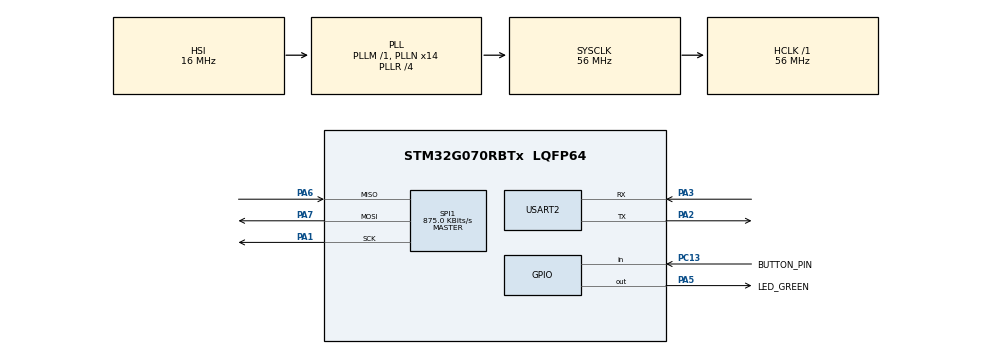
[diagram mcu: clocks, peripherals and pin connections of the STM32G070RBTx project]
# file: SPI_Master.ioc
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Mcu.Family=STM32G0
Mcu.Name=STM32G070RBTx
Mcu.Package=LQFP64
NVIC.SPI1_IRQn=true\:0\:0\:false\:false\:true\:true\:true\:true
PA1.GPIO_Speed=GPIO_SPEED_FREQ_VERY_HIGH
PA1.Mode=Full_Duplex_Master
PA1.Signal=SPI1_SCK
PA13.GPIO_Label=TMS
PA13.Mode=Serial_Wire
PA13.Signal=SYS_SWDIO
PA14-BOOT0.GPIO_Label=TCK
PA14-BOOT0.Mode=Serial_Wire
PA14-BOOT0.Signal=SYS_SWCLK
PA2.GPIO_PuPd=GPIO_PULLUP
PA2.Mode=Asynchronous
PA2.Signal=USART2_TX
PA3.GPIO_PuPd=GPIO_PULLUP
PA3.Mode=Asynchronous
PA3.Signal=USART2_RX
PA5.GPIO_Label=LED_GREEN
PA5.GPIO_Speed=GPIO_SPEED_FREQ_HIGH
PA5.Signal=GPIO_Output
PA6.GPIO_Speed=GPIO_SPEED_FREQ_VERY_HIGH
PA6.Mode=Full_Duplex_Master
PA6.Signal=SPI1_MISO
PA7.GPIO_Speed=GPIO_SPEED_FREQ_VERY_HIGH
PA7.Mode=Full_Duplex_Master
PA7.Signal=SPI1_MOSI
PC13.GPIO_Label=BUTTON_PIN
PC13.Signal=GPIO_Input
PC14-OSC32_IN\ (PC14).Mode=LSE-External-Oscillator
PC14-OSC32_IN\ (PC14).Signal=RCC_OSC32_IN
PC15-OSC32_OUT\ (PC15).Mode=LSE-External-Oscillator
PC15-OSC32_OUT\ (PC15).Signal=RCC_OSC32_OUT
PF0-OSC_IN\ (PF0).GPIO_Label=MCO
PF0-OSC_IN\ (PF0).Mode=HSE-External-Clock-Source
PF0-OSC_IN\ (PF0).Signal=RCC_OSC_IN
ProjectManager.HeapSize=0x200
ProjectManager.StackSize=0x400
ProjectManager.TargetToolchain=STM32CubeIDE
RCC.ADCFreq_Value=56000000
RCC.AHBFreq_Value=56000000
RCC.CortexFreq_Value=56000000
RCC.EXTERNAL_CLOCK_VALUE=12288000
RCC.HCLKFreq_Value=56000000
RCC.HSE_VALUE=8000000
RCC.HSI_VALUE=16000000
RCC.PLLN=14
RCC.PLLR=RCC_PLLR_DIV4
RCC.SYSCLKFreq_VALUE=56000000
RCC.SYSCLKSource=RCC_SYSCLKSOURCE_PLLCLK
RCC.VCOOutputFreq_Value=224000000
SPI1.BaudRatePrescaler=SPI_BAUDRATEPRESCALER_64
SPI1.CalculateBaudRate=875.0 KBits/s
SPI1.Direction=SPI_DIRECTION_2LINES
SPI1.Mode=SPI_MODE_MASTER
SPI1.VirtualType=VM_MASTER
USART2.VirtualMode-Asynchronous=VM_ASYNC
USART2.WordLength=WORDLENGTH_7B
board=NUCLEO-G070RB

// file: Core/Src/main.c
/* USER CODE BEGIN Header */
/**
  ******************************************************************************
  * @file           : main.c
  * @brief          : Main program body
  ******************************************************************************
  * @attention
  *
  * Copyright (c) 2024 STMicroelectronics.
  * All rights reserved.
  *
  * This software is licensed under terms that can be found in the LICENSE file
  * in the root directory of this software component.
  * If no LICENSE file comes with this software, it is provided AS-IS.
  *
  ******************************************************************************
  */
/* USER CODE END Header */
#include "main.h"

SPI_HandleTypeDef hspi1;

UART_HandleTypeDef huart2;

/* USER CODE BEGIN PV */
/* Private variables */
uint8_t TX_Buffer = 6 ; // DATA to send
/* USER CODE END PV */

void SystemClock_Config(void);
static void MX_GPIO_Init(void);
static void MX_USART2_UART_Init(void);
static void MX_SPI1_Init(void);

int main(void)
{

  /* MCU Configuration--------------------------------------------------------*/

  /* Reset of all peripherals, Initializes the Flash interface and the Systick. */
  HAL_Init();

  /* Configure the system clock */
  SystemClock_Config();

  /* Initialize all configured peripherals */
  MX_GPIO_Init();
  MX_USART2_UART_Init();
  MX_SPI1_Init();
  /* USER CODE BEGIN 2 */
  /* Configure LED4 */
  while (HAL_GPIO_ReadPin(BUTTON_PIN_GPIO_Port, BUTTON_PIN_Pin))
    {
	  HAL_GPIO_TogglePin(LED_GREEN_GPIO_Port, LED_GREEN_Pin);
      HAL_Delay(100);
    }
  HAL_GPIO_WritePin(LED_GREEN_GPIO_Port, LED_GREEN_Pin, 0);

//
  HAL_SPI_Transmit(&hspi1, &TX_Buffer, 1,1000); //Sending in Blocking mode
  HAL_Delay(100);
  /* USER CODE END 2 */

  /* Infinite loop */
  /* USER CODE BEGIN WHILE */
  while (1)
  {
//	  HAL_SPI_Transmit(&hspi1, &TX_Buffer, 1,1000); //Sending in Blocking mode
//	  HAL_Delay(100);
//

    /* USER CODE END WHILE */

  }
}

void SystemClock_Config(void)
{
  RCC_OscInitTypeDef RCC_OscInitStruct = {0};
  RCC_ClkInitTypeDef RCC_ClkInitStruct = {0};

  /** Configure the main internal regulator output voltage
  */
  HAL_PWREx_ControlVoltageScaling(PWR_REGULATOR_VOLTAGE_SCALE1);

  /** Initializes the RCC Oscillators according to the specified parameters
  * in the RCC_OscInitTypeDef structure.
  */
  RCC_OscInitStruct.OscillatorType = RCC_OSCILLATORTYPE_HSI;
  RCC_OscInitStruct.HSIState = RCC_HSI_ON;
  RCC_OscInitStruct.HSIDiv = RCC_HSI_DIV1;
  RCC_OscInitStruct.HSICalibrationValue = RCC_HSICALIBRATION_DEFAULT;
  RCC_OscInitStruct.PLL.PLLState = RCC_PLL_ON;
  RCC_OscInitStruct.PLL.PLLSource = RCC_PLLSOURCE_HSI;
  RCC_OscInitStruct.PLL.PLLM = RCC_PLLM_DIV1;
  RCC_OscInitStruct.PLL.PLLN = 14;
  RCC_OscInitStruct.PLL.PLLP = RCC_PLLP_DIV2;
  RCC_OscInitStruct.PLL.PLLR = RCC_PLLR_DIV4;
  if (HAL_RCC_OscConfig(&RCC_OscInitStruct) != HAL_OK)
  {
    Error_Handler();
  }

  /** Initializes the CPU, AHB and APB buses clocks
  */
  RCC_ClkInitStruct.ClockType = RCC_CLOCKTYPE_HCLK|RCC_CLOCKTYPE_SYSCLK
                              |RCC_CLOCKTYPE_PCLK1;
  RCC_ClkInitStruct.SYSCLKSource = RCC_SYSCLKSOURCE_PLLCLK;
  RCC_ClkInitStruct.AHBCLKDivider = RCC_SYSCLK_DIV1;
  RCC_ClkInitStruct.APB1CLKDivider = RCC_HCLK_DIV1;

  if (HAL_RCC_ClockConfig(&RCC_ClkInitStruct, FLASH_LATENCY_2) != HAL_OK)
  {
    Error_Handler();
  }
}

static void MX_SPI1_Init(void)
{

  /* SPI1 parameter configuration*/
  hspi1.Instance = SPI1;
  hspi1.Init.Mode = SPI_MODE_MASTER;
  hspi1.Init.Direction = SPI_DIRECTION_2LINES;
  hspi1.Init.DataSize = SPI_DATASIZE_4BIT;
  hspi1.Init.CLKPolarity = SPI_POLARITY_LOW;
  hspi1.Init.CLKPhase = SPI_PHASE_1EDGE;
  hspi1.Init.NSS = SPI_NSS_SOFT;
  hspi1.Init.BaudRatePrescaler = SPI_BAUDRATEPRESCALER_64;
  hspi1.Init.FirstBit = SPI_FIRSTBIT_MSB;
  hspi1.Init.TIMode = SPI_TIMODE_DISABLE;
  hspi1.Init.CRCCalculation = SPI_CRCCALCULATION_DISABLE;
  hspi1.Init.CRCPolynomial = 7;
  hspi1.Init.CRCLength = SPI_CRC_LENGTH_DATASIZE;
  hspi1.Init.NSSPMode = SPI_NSS_PULSE_ENABLE;
  if (HAL_SPI_Init(&hspi1) != HAL_OK)
  {
    Error_Handler();
  }

}

static void MX_USART2_UART_Init(void)
{

  huart2.Instance = USART2;
  huart2.Init.BaudRate = 115200;
  huart2.Init.WordLength = UART_WORDLENGTH_7B;
  huart2.Init.StopBits = UART_STOPBITS_1;
  huart2.Init.Parity = UART_PARITY_NONE;
  huart2.Init.Mode = UART_MODE_TX_RX;
  huart2.Init.HwFlowCtl = UART_HWCONTROL_NONE;
  huart2.Init.OverSampling = UART_OVERSAMPLING_16;
  huart2.Init.OneBitSampling = UART_ONE_BIT_SAMPLE_DISABLE;
  huart2.Init.ClockPrescaler = UART_PRESCALER_DIV1;
  huart2.AdvancedInit.AdvFeatureInit = UART_ADVFEATURE_NO_INIT;
  if (HAL_UART_Init(&huart2) != HAL_OK)
  {
    Error_Handler();
  }
  if (HAL_UARTEx_SetTxFifoThreshold(&huart2, UART_TXFIFO_THRESHOLD_1_8) != HAL_OK)
  {
    Error_Handler();
  }
  if (HAL_UARTEx_SetRxFifoThreshold(&huart2, UART_RXFIFO_THRESHOLD_1_8) != HAL_OK)
  {
    Error_Handler();
  }
  if (HAL_UARTEx_DisableFifoMode(&huart2) != HAL_OK)
  {
    Error_Handler();
  }

}

static void MX_GPIO_Init(void)
{
  GPIO_InitTypeDef GPIO_InitStruct = {0};

  /* GPIO Ports Clock Enable */
  __HAL_RCC_GPIOC_CLK_ENABLE();
  __HAL_RCC_GPIOF_CLK_ENABLE();
  __HAL_RCC_GPIOA_CLK_ENABLE();

  /*Configure GPIO pin Output Level */
  HAL_GPIO_WritePin(LED_GREEN_GPIO_Port, LED_GREEN_Pin, GPIO_PIN_RESET);

  /*Configure GPIO pin : BUTTON_PIN_Pin */
  GPIO_InitStruct.Pin = BUTTON_PIN_Pin;
  GPIO_InitStruct.Mode = GPIO_MODE_INPUT;
  GPIO_InitStruct.Pull = GPIO_NOPULL;
  HAL_GPIO_Init(BUTTON_PIN_GPIO_Port, &GPIO_InitStruct);

  /*Configure GPIO pin : LED_GREEN_Pin */
  GPIO_InitStruct.Pin = LED_GREEN_Pin;
  GPIO_InitStruct.Mode = GPIO_MODE_OUTPUT_PP;
  GPIO_InitStruct.Pull = GPIO_NOPULL;
  GPIO_InitStruct.Speed = GPIO_SPEED_FREQ_HIGH;
  HAL_GPIO_Init(LED_GREEN_GPIO_Port, &GPIO_InitStruct);

}

void Error_Handler(void)
{
  __disable_irq();
  while (1)
  {
  }
}
